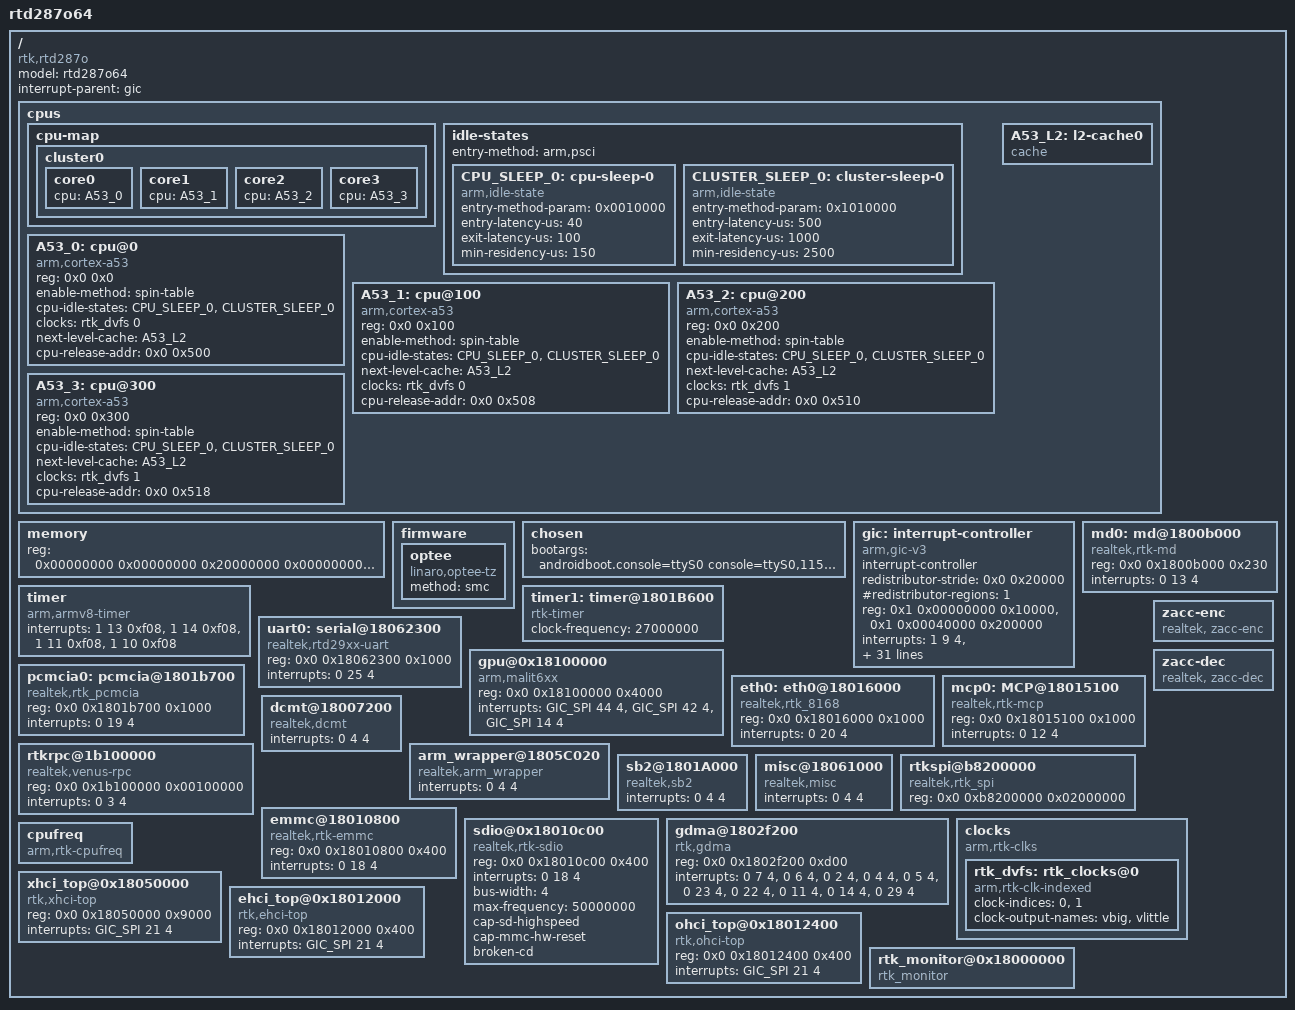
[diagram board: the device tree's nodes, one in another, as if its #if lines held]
/*
 * rtd287x device tree source
 */

#include <dt-bindings/interrupt-controller/irq.h>
#include <dt-bindings/interrupt-controller/arm-gic.h>
#include <generated/autoconf.h>

/dts-v1/;

/include/ "skeleton.dtsi"

#ifdef CONFIG_REALTEK_2K_MODEL_ENABLED
#include "rtd287o_mem_layout_2k.dtsi"
#else
#include "rtd287o_mem_layout.dtsi"
#endif

/ {
	model = "rtd287o64";
	compatible = "rtk,rtd287o";
	interrupt-parent = <&gic>;

	#address-cells = <2>;
	#size-cells = <1>;

	cpus {

        	#address-cells = <2>;
        	#size-cells = <0>;

		cpu-map {
			cluster0: cluster0 {
				#cooling-cells = <2>; /* min followed by max */

				core0 {
					cpu = <&A53_0>;
				};

				core1 {
					cpu = <&A53_1>;
				};
				core2 {
					cpu = <&A53_2>;
				};
				core3 {
					cpu = <&A53_3>;
				}; 
			};
		};

		idle-states {
			entry-method = "arm,psci";

			CPU_SLEEP_0: cpu-sleep-0 {
				compatible = "arm,idle-state";
				entry-method-param = <0x0010000>;
				entry-latency-us = <40>;
				exit-latency-us = <100>;
				min-residency-us = <150>;
			};

			CLUSTER_SLEEP_0: cluster-sleep-0 {
				compatible = "arm,idle-state";
				entry-method-param = <0x1010000>;
				entry-latency-us = <500>;
				exit-latency-us = <1000>;
				min-residency-us = <2500>;
			};
		};

		A53_0: cpu@0 {
			compatible = "arm,cortex-a53","arm,armv8";
			reg = <0x0 0x0>;
			device_type = "cpu";
			enable-method = "spin-table";
			cpu-idle-states = <&CPU_SLEEP_0 &CLUSTER_SLEEP_0>;
                        clocks = <&rtk_dvfs 0>;
			clock-names = "vlittle";
                        next-level-cache = <&A53_L2>;
			cpu-release-addr = <0x0 0x500>;
		};

		A53_1: cpu@100 {
			compatible = "arm,cortex-a53","arm,armv8";
			reg = <0x0 0x100>;
			device_type = "cpu";
			enable-method = "spin-table";
			cpu-idle-states = <&CPU_SLEEP_0 &CLUSTER_SLEEP_0>;
			clock-names = "vlittle";
                        next-level-cache = <&A53_L2>;
                        clocks = <&rtk_dvfs 0>;
			cpu-release-addr = <0x0 0x508>;
		};

		A53_2: cpu@200 {
			compatible = "arm,cortex-a53","arm,armv8";
			reg = <0x0 0x200>;
			device_type = "cpu";
			enable-method = "spin-table";
			cpu-idle-states = <&CPU_SLEEP_0 &CLUSTER_SLEEP_0>;
                        next-level-cache = <&A53_L2>;
			clock-names = "vlittle";
                        clocks = <&rtk_dvfs 1>;
			cpu-release-addr = <0x0 0x510>;
		};

		A53_3: cpu@300 {
			compatible = "arm,cortex-a53","arm,armv8";
			reg = <0x0 0x300>;
			device_type = "cpu";
			enable-method = "spin-table";
			cpu-idle-states = <&CPU_SLEEP_0 &CLUSTER_SLEEP_0>;
                        next-level-cache = <&A53_L2>;
			clock-names = "vlittle";
                        clocks = <&rtk_dvfs 1>;
			cpu-release-addr = <0x0 0x518>;
		};

		A53_L2: l2-cache0 {
                        compatible = "cache";
                };

	};

	/*  memory will be updated by atags from bootcode */
	memory {
		device_type = "memory";
		reg = <0x00000000 0x00000000 0x20000000
		       0x00000000 0x20000000 0x40000000>;
	};

        firmware {
                optee {
                        compatible = "linaro,optee-tz";
                        method = "smc";
                };
        };

	chosen {
		/*  bootargs will be updated by atags from bootcode */
		bootargs ="androidboot.console=ttyS0 console=ttyS0,115200 envp=74100 flashtype=emmc mmcparts=rtkemmc:3436544k,655360k(/system),4096k(/usr/local/etc) root=/dev/mmcblk0p1 rootfstype=ext4 ro rootwait reclaim=72M@32M last_image=8M@160M earlyprintk=uart8250-32bit,0x18062300 ac_on";
	};


 gic:interrupt-controller {
                compatible = "arm,gic-v3";
                #interrupt-cells = <0x3>;
                #address-cells = <0x2>;
                #size-cells = <0x2>;
                interrupt-controller;
                redistributor-stride = <0x0 0x20000>;
                #redistributor-regions = <1>;
                reg = <0x1 0x00000000  0x10000>,       // GICD
                      <0x1 0x00040000  0x200000>;      // GICR
                interrupts = <1 9 4>,
                <GIC_PPI 13 IRQ_TYPE_LEVEL_LOW>,
                <GIC_PPI 14 IRQ_TYPE_LEVEL_LOW>,
                <GIC_PPI 11 IRQ_TYPE_LEVEL_LOW>,
                <GIC_PPI 10 IRQ_TYPE_LEVEL_LOW>,
                <GIC_SPI 0 4>, <GIC_SPI 1 4>,<GIC_SPI 2 4>,<GIC_SPI 3 4>,<GIC_SPI 4 4>,<GIC_SPI 5 4>,<GIC_SPI 6 4>,<GIC_SPI 7 4>,<GIC_SPI 8 4>,<GIC_SPI 9 4>,
                <GIC_SPI 10 4>, <GIC_SPI 11 4>,<GIC_SPI 12 4>,<GIC_SPI 13 4>,<GIC_SPI 14 4>,<GIC_SPI 5 4>, <GIC_SPI 16 4>,<GIC_SPI 17 4>,<GIC_SPI 18 4>,<GIC_SPI 19 4>,
                <GIC_SPI 20 4>, <GIC_SPI 21 4>,<GIC_SPI 22 4>,<GIC_SPI 23 4>,<GIC_SPI 24 4>,<GIC_SPI 5 4>, <GIC_SPI 26 4>,<GIC_SPI 27 4>,<GIC_SPI 28 4>,<GIC_SPI 29 4>,
                <GIC_SPI 30 4>, <GIC_SPI 31 4>,<GIC_SPI 32 4>,<GIC_SPI 33 4>,<GIC_SPI 34 4>,<GIC_SPI 5 4>, <GIC_SPI 36 4>,<GIC_SPI 37 4>,<GIC_SPI 38 4>,<GIC_SPI 39 4>,
                <GIC_SPI 40 4>, <GIC_SPI 41 4>,<GIC_SPI 42 4>,<GIC_SPI 43 4>,<GIC_SPI 44 4>,<GIC_SPI 45 4>, <GIC_SPI 46 4>,<GIC_SPI 47 4>,<GIC_SPI 48 4>,<GIC_SPI 49 4>,
                <GIC_SPI 50 4>, <GIC_SPI 51 4>,<GIC_SPI 52 4>,<GIC_SPI 53 4>,<GIC_SPI 54 4>,<GIC_SPI 55 4>, <GIC_SPI 56 4>,<GIC_SPI 57 4>,<GIC_SPI 58 4>,<GIC_SPI 59 4>,
                <GIC_SPI 60 4>, <GIC_SPI 61 4>,<GIC_SPI 62 4>,<GIC_SPI 63 4>,<GIC_SPI 64 4>,<GIC_SPI 65 4>, <GIC_SPI 66 4>,<GIC_SPI 67 4>,<GIC_SPI 68 4>,<GIC_SPI 69 4>,
                <GIC_SPI 70 4>, <GIC_SPI 71 4>,<GIC_SPI 72 4>,<GIC_SPI 73 4>,<GIC_SPI 74 4>,<GIC_SPI 75 4>, <GIC_SPI 76 4>,<GIC_SPI 77 4>,<GIC_SPI 78 4>,<GIC_SPI 79 4>;

        };

        timer {
                compatible = "arm,armv8-timer";
                interrupts = <1 13 0xf08>,
                             <1 14 0xf08>,
                             <1 11 0xf08>,
                             <1 10 0xf08>;
        };

       timer1: timer@1801B600 {
               compatible = "rtk-timer";
               /* PPI secure/nonsecure IRQ, active low level-sensitive ,following not used now*/
               clock-frequency = <27000000>;
       };


	uart0:serial@18062300 {
		compatible = "realtek,rtd29xx-uart";
		reg = <0x0 0x18062300 0x1000>;
		interrupts = <0 25 4>;
	};

	gpu@0x18100000 {
	compatible = "arm,malit6xx", "arm,mali-midgard";
	reg = <0x0 0x18100000 0x4000>;
	interrupts = <GIC_SPI 44 4>, <GIC_SPI 42 4>, <GIC_SPI 14 4>;
	interrupt-names = "JOB", "MMU", "GPU";

	//clocks = <&pclk_mali>;
			//clocks = <10M>
	clock-names = "clk_mali";
	};
	pcmcia0:pcmcia@1801b700 {
		compatible = "realtek,rtk_pcmcia";
		reg = <0x0 0x1801b700 0x1000>;
		interrupts = <0 19 4>;
	};

	eth0:eth0@18016000 {
		compatible = "realtek,rtk_8168";
		reg = <0x0 0x18016000 0x1000>;
		interrupts = <0 20 4>;
	};

	md0:md@1800b000 {
                compatible = "realtek,rtk-md";
                reg = <0x0 0x1800b000 0x230>;
                interrupts = <0 13 4>;
	};

        mcp0:MCP@18015100 {
                compatible = "realtek,rtk-mcp";
                reg = <0x0 0x18015100 0x1000>;
                interrupts = <0 12 4>;
        };

	rtkrpc@1b100000 {
		compatible = "realtek,venus-rpc";
		reg = <0x0 0x1b100000 0x00100000>;
		interrupts = <0 3 4>;
	};

	dcmt@18007200 {
		compatible = "realtek,dcmt";
		interrupts = <0 4 4>;
	};

        arm_wrapper@1805C020 {
                compatible = "realtek,arm_wrapper";
                interrupts = <0 4 4>;
        };

        sb2@1801A000 {
                compatible = "realtek,sb2";
                interrupts = <0 4 4>;
        };

	zacc-enc{
		compatible = "realtek, zacc-enc";
	};

	zacc-dec{
		compatible = "realtek, zacc-dec";
	};

        misc@18061000 {
                compatible = "realtek,misc";
                interrupts = <0 4 4>;
        };

	rtkspi@b8200000 {
		#address-cells = <2>;
                #size-cells = <2>;
		compatible = "realtek,rtk_spi";
		reg = <0x0 0xb8200000 0x02000000>;
        };
        
        emmc@18010800 {
                compatible = "realtek,rtk-emmc";
                reg = <0x0 0x18010800 0x400>;
                interrupts = <0 18 4>;
        };

	sdio@0x18010c00 {
		compatible = "realtek,rtk-sdio";
		reg = <0x0 0x18010c00 0x400>;
		interrupts = <0 18 4>;
		bus-width = <4>;
		max-frequency = <50000000>;
		cap-sd-highspeed;
		cap-mmc-hw-reset;
		broken-cd;
	};
	gdma@1802f200 {
                compatible = "rtk,gdma";
                reg = <0x0 0x1802f200 0xd00>;
                interrupts = <0 7 4>,
                            <0 6 4>,
                            <0 2 4>,
                            <0 4 4>,
                            <0 5 4>,
                            <0 23 4>,
                            <0 22 4>,
                            <0 11 4>,
                            <0 14 4>,
                            <0 29 4>;
	};

/*


	thermal@0xb8000000 {
        	compatible = "rtk_rtk299s-tmu";
        	reg = <0xb8000000 0x200
        	       0xb8000200 0x200>;
        	status = "okay";
        };

*/
       clocks {
               compatible = "arm,rtk-clks";

                rtk_dvfs: rtk_clocks@0 {
                        compatible = "arm,rtk-clk-indexed";
                        #clock-cells = <1>;
                        clock-indices = <0>, <1>;
                        clock-output-names = "vbig", "vlittle";
                };

/*                rtk_clk: rtk_clocks@2 {
                        compatible = "arm,rtk-clk-range";
                        #clock-cells = <1>;
                        clock-indices = <2>, <3>;
                        frequency-range = <23750000 165000000>;
                        clock-output-names = "pxlclk0", "pxlclk1";
                };*/
       };

        cpufreq {
                compatible = "arm,rtk-cpufreq";
        };

	xhci_top@0x18050000 {
		compatible = "rtk,xhci-top";
		reg = <0x0 0x18050000 0x9000>;
		interrupts = <GIC_SPI 21 4>;
	};

	ehci_top@0x18012000 {
		compatible = "rtk,ehci-top";
		reg = <0x0 0x18012000 0x400>;
		interrupts = <GIC_SPI 21 4>;
	};

	ohci_top@0x18012400 {
		compatible = "rtk,ohci-top";
		reg = <0x0 0x18012400 0x400>;
		interrupts = <GIC_SPI 21 4>;
	};

        rtk_monitor@0x18000000 {
                compatible = "rtk_monitor";
                status = "okay";
        };



};

